VERSION ""

NS_ :

BS_:

BU_:

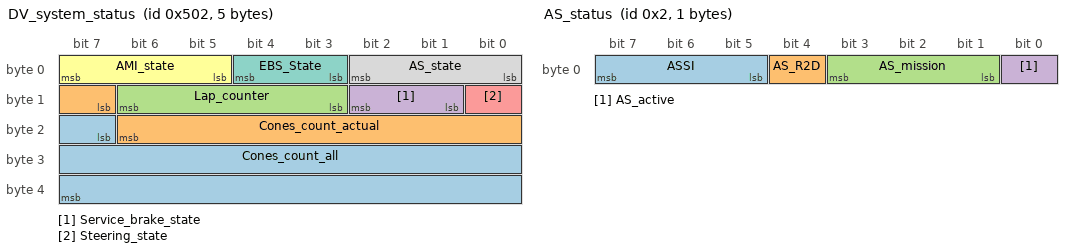
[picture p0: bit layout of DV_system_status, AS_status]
BO_ 1282 DV_system_status: 5 Vector__XXX
 SG_ Cones_count_all : 23|17@1+ (1,0) [0|16] "" Vector__XXX
 SG_ Cones_count_actual : 15|8@1+ (1,0) [0|7] "" Vector__XXX
 SG_ Lap_counter : 11|4@1+ (1,0) [0|3] "" Vector__XXX
 SG_ Service_brake_state : 9|2@1+ (1,0) [0|1] "" Vector__XXX
 SG_ Steering_state : 8|1@1+ (1,0) [0|0] "" Vector__XXX
 SG_ AMI_state : 5|3@1+ (1,0) [0|2] "" Vector__XXX
 SG_ EBS_State : 3|2@1+ (1,0) [0|1] "" Vector__XXX
 SG_ AS_state : 0|3@1+ (1,0) [0|2] "" Vector__XXX

BO_ 2 AS_status: 1 Vector__XXX
 SG_ ASSI : 5|3@1+ (1,0) [0|7] "enum" Vector__XXX
 SG_ AS_R2D : 4|1@1+ (1,0) [0|1] "bool" Vector__XXX
 SG_ AS_mission : 1|3@1+ (1,0) [0|7] "enum" Vector__XXX
 SG_ AS_active : 0|1@1+ (1,0) [0|1] "bool" Vector__XXX

BO_ 1 AS_Setpt_steer: 3 Vector__XXX
 SG_ AS_steer_ang : 0|24@1- (0.005,0) [-41943.04|41943.035] "rad" Vector__XXX

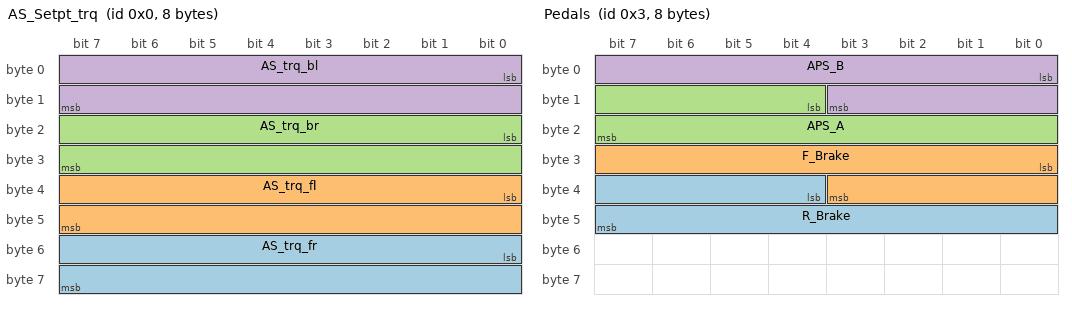
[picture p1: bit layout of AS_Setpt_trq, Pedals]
BO_ 0 AS_Setpt_trq: 8 Vector__XXX
 SG_ AS_trq_fr : 48|16@1- (0.0098,0) [-321.1264|321.1166] "Nm" Vector__XXX
 SG_ AS_trq_fl : 32|16@1- (0.0098,0) [-321.1264|321.1166] "Nm" Vector__XXX
 SG_ AS_trq_br : 16|16@1- (0.0098,0) [-321.1264|321.1166] "Nm" Vector__XXX
 SG_ AS_trq_bl : 0|16@1- (0.0098,0) [-321.1264|321.1166] "Nm" Vector__XXX

BO_ 3 Pedals: 8 Vector__XXX
 SG_ R_Brake : 36|12@1+ (0.6103,-249.978) [0|2249.2005] "psi" Vector__XXX
 SG_ F_Brake : 24|12@1+ (0.6103,-249.978) [0|2249.2005] "psi" Vector__XXX
 SG_ APS_A : 12|12@1+ (1,0) [0|4095] "percent" Vector__XXX
 SG_ APS_B : 0|12@1+ (1,0) [0|4095] "percent" Vector__XXX

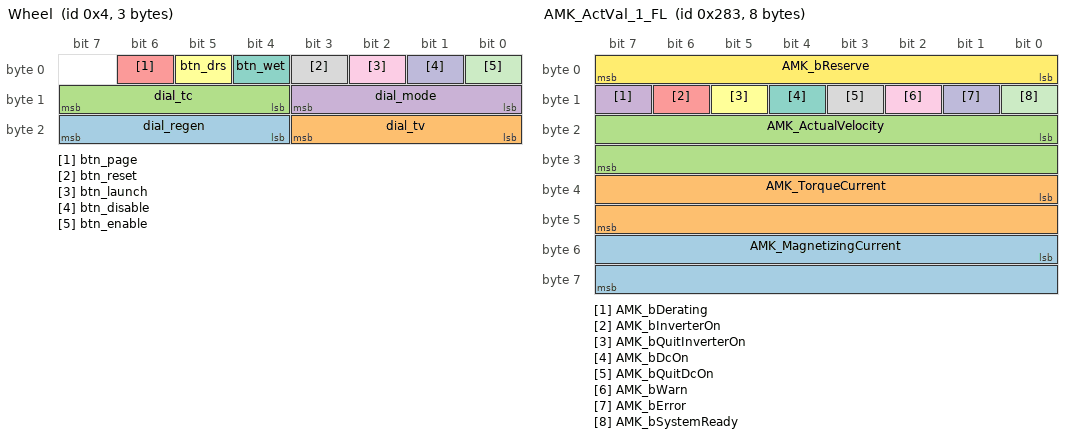
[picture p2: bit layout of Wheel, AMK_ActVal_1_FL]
BO_ 4 Wheel: 3 Vector__XXX
 SG_ dial_regen : 20|4@1+ (1,0) [0|15] "" Vector__XXX
 SG_ dial_tv : 16|4@1+ (1,0) [0|15] "" Vector__XXX
 SG_ dial_tc : 12|4@1+ (1,0) [0|15] "" Vector__XXX
 SG_ dial_mode : 8|4@1+ (1,0) [0|15] "" Vector__XXX
 SG_ btn_page : 6|1@1+ (1,0) [0|1] "" Vector__XXX
 SG_ btn_drs : 5|1@1+ (1,0) [0|1] "" Vector__XXX
 SG_ btn_wet : 4|1@1+ (1,0) [0|1] "" Vector__XXX
 SG_ btn_reset : 3|1@1+ (1,0) [0|1] "" Vector__XXX
 SG_ btn_launch : 2|1@1+ (1,0) [0|1] "" Vector__XXX
 SG_ btn_disable : 1|1@1+ (1,0) [0|1] "" Vector__XXX
 SG_ btn_enable : 0|1@1+ (1,0) [0|1] "" Vector__XXX

BO_ 643 AMK_ActVal_1_FL: 8 Vector__XXX
 SG_ AMK_MagnetizingCurrent : 48|16@1- (1,0) [-32768|32767] "" Vector__XXX
 SG_ AMK_TorqueCurrent : 32|16@1- (1,0) [-32768|32767] "" Vector__XXX
 SG_ AMK_ActualVelocity : 16|16@1- (1,0) [-32768|32767] "rpm" Vector__XXX
 SG_ AMK_bDerating : 15|1@1+ (1,0) [0|1] "" Vector__XXX
 SG_ AMK_bInverterOn : 14|1@1+ (1,0) [0|1] "" Vector__XXX
 SG_ AMK_bQuitInverterOn : 13|1@1+ (1,0) [0|1] "" Vector__XXX
 SG_ AMK_bDcOn : 12|1@1+ (1,0) [0|1] "" Vector__XXX
 SG_ AMK_bQuitDcOn : 11|1@1+ (1,0) [0|1] "" Vector__XXX
 SG_ AMK_bWarn : 10|1@1+ (1,0) [0|1] "" Vector__XXX
 SG_ AMK_bError : 9|1@1+ (1,0) [0|1] "" Vector__XXX
 SG_ AMK_bSystemReady : 8|1@1+ (1,0) [0|1] "" Vector__XXX
 SG_ AMK_bReserve : 0|8@1+ (1,0) [0|255] "" Vector__XXX

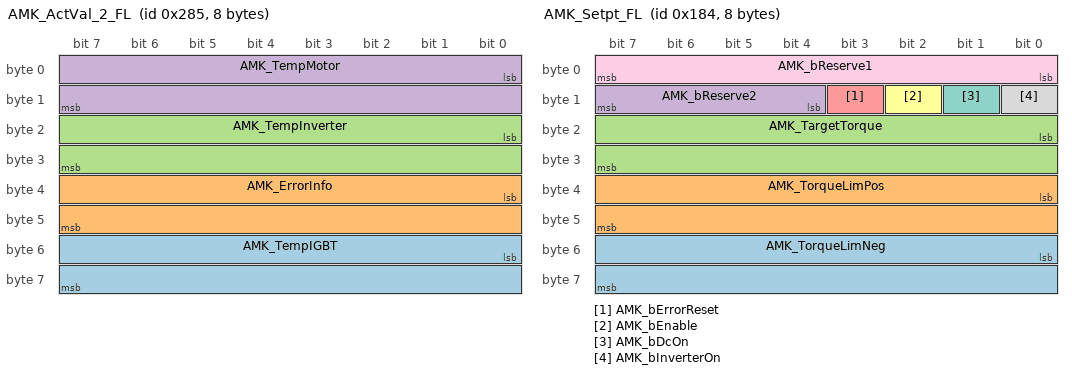
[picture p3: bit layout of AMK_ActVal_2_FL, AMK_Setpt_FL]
BO_ 645 AMK_ActVal_2_FL: 8 Vector__XXX
 SG_ AMK_TempIGBT : 48|16@1- (0.1,0) [-3276.8|3276.7] "C" Vector__XXX
 SG_ AMK_ErrorInfo : 32|16@1+ (1,0) [0|65535] "" Vector__XXX
 SG_ AMK_TempInverter : 16|16@1- (0.1,0) [-3276.8|3276.7] "C" Vector__XXX
 SG_ AMK_TempMotor : 0|16@1- (0.1,0) [-3276.8|3276.7] "C" Vector__XXX

BO_ 388 AMK_Setpt_FL: 8 Vector__XXX
 SG_ AMK_TorqueLimNeg : 48|16@1- (0.0098,0) [-321.1264|321.1166] "Nm" Vector__XXX
 SG_ AMK_TorqueLimPos : 32|16@1- (0.0098,0) [-321.1264|321.1166] "Nm" Vector__XXX
 SG_ AMK_TargetTorque : 16|16@1- (0.0098,0) [-321.1264|321.1166] "Nm" Vector__XXX
 SG_ AMK_bReserve2 : 12|4@1+ (1,0) [0|15] "" Vector__XXX
 SG_ AMK_bErrorReset : 11|1@1+ (1,0) [0|1] "" Vector__XXX
 SG_ AMK_bEnable : 10|1@1+ (1,0) [0|1] "" Vector__XXX
 SG_ AMK_bDcOn : 9|1@1+ (1,0) [0|1] "" Vector__XXX
 SG_ AMK_bInverterOn : 8|1@1+ (1,0) [0|1] "" Vector__XXX
 SG_ AMK_bReserve1 : 0|8@1+ (1,0) [0|255] "" Vector__XXX

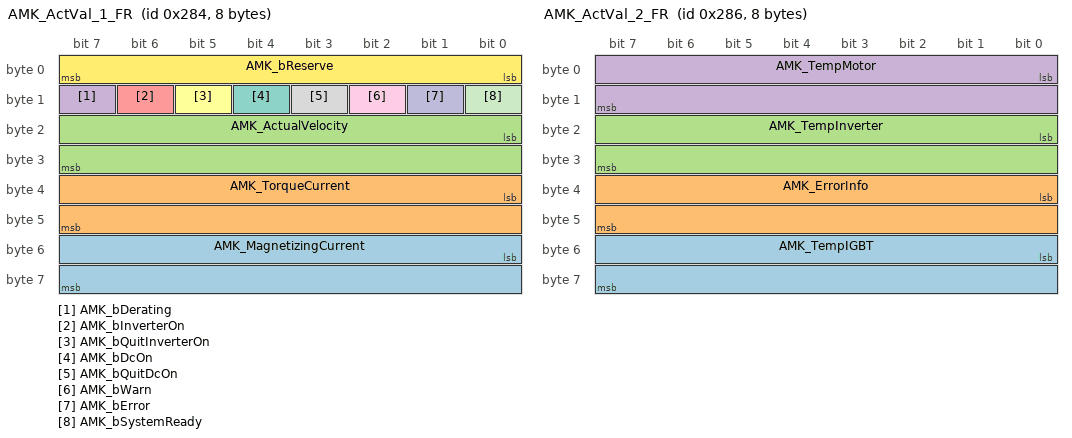
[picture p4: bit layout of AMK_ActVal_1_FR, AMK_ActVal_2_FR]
BO_ 644 AMK_ActVal_1_FR: 8 Vector__XXX
 SG_ AMK_MagnetizingCurrent : 48|16@1- (1,0) [-32768|32767] "" Vector__XXX
 SG_ AMK_TorqueCurrent : 32|16@1- (1,0) [-32768|32767] "" Vector__XXX
 SG_ AMK_ActualVelocity : 16|16@1- (1,0) [-32768|32767] "rpm" Vector__XXX
 SG_ AMK_bDerating : 15|1@1+ (1,0) [0|1] "" Vector__XXX
 SG_ AMK_bInverterOn : 14|1@1+ (1,0) [0|1] "" Vector__XXX
 SG_ AMK_bQuitInverterOn : 13|1@1+ (1,0) [0|1] "" Vector__XXX
 SG_ AMK_bDcOn : 12|1@1+ (1,0) [0|1] "" Vector__XXX
 SG_ AMK_bQuitDcOn : 11|1@1+ (1,0) [0|1] "" Vector__XXX
 SG_ AMK_bWarn : 10|1@1+ (1,0) [0|1] "" Vector__XXX
 SG_ AMK_bError : 9|1@1+ (1,0) [0|1] "" Vector__XXX
 SG_ AMK_bSystemReady : 8|1@1+ (1,0) [0|1] "" Vector__XXX
 SG_ AMK_bReserve : 0|8@1+ (1,0) [0|255] "" Vector__XXX

BO_ 646 AMK_ActVal_2_FR: 8 Vector__XXX
 SG_ AMK_TempIGBT : 48|16@1- (0.1,0) [-3276.8|3276.7] "C" Vector__XXX
 SG_ AMK_ErrorInfo : 32|16@1+ (1,0) [0|65535] "" Vector__XXX
 SG_ AMK_TempInverter : 16|16@1- (0.1,0) [-3276.8|3276.7] "C" Vector__XXX
 SG_ AMK_TempMotor : 0|16@1- (0.1,0) [-3276.8|3276.7] "C" Vector__XXX

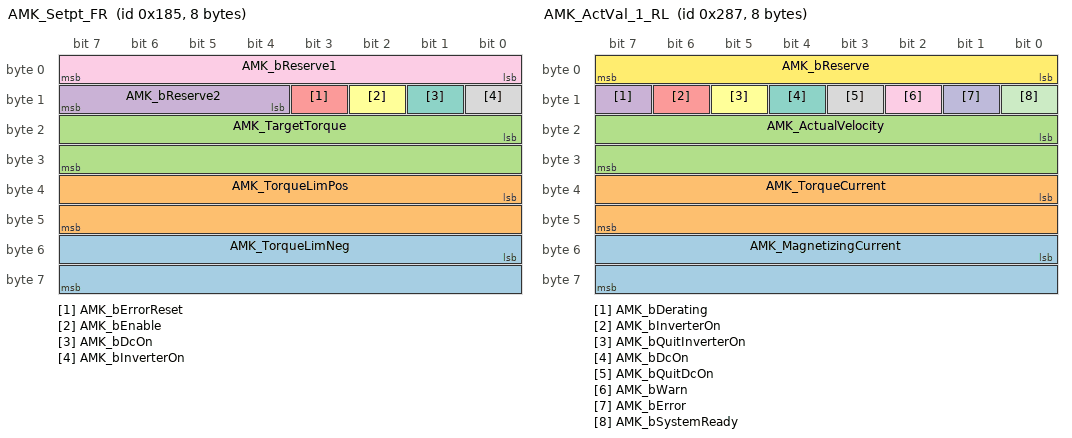
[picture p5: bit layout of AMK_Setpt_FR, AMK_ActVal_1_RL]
BO_ 389 AMK_Setpt_FR: 8 Vector__XXX
 SG_ AMK_TorqueLimNeg : 48|16@1- (0.0098,0) [-321.1264|321.1166] "Nm" Vector__XXX
 SG_ AMK_TorqueLimPos : 32|16@1- (0.0098,0) [-321.1264|321.1166] "Nm" Vector__XXX
 SG_ AMK_TargetTorque : 16|16@1- (0.0098,0) [-321.1264|321.1166] "Nm" Vector__XXX
 SG_ AMK_bReserve2 : 12|4@1+ (1,0) [0|15] "" Vector__XXX
 SG_ AMK_bErrorReset : 11|1@1+ (1,0) [0|1] "" Vector__XXX
 SG_ AMK_bEnable : 10|1@1+ (1,0) [0|1] "" Vector__XXX
 SG_ AMK_bDcOn : 9|1@1+ (1,0) [0|1] "" Vector__XXX
 SG_ AMK_bInverterOn : 8|1@1+ (1,0) [0|1] "" Vector__XXX
 SG_ AMK_bReserve1 : 0|8@1+ (1,0) [0|255] "" Vector__XXX

BO_ 647 AMK_ActVal_1_RL: 8 Vector__XXX
 SG_ AMK_MagnetizingCurrent : 48|16@1- (1,0) [-32768|32767] "" Vector__XXX
 SG_ AMK_TorqueCurrent : 32|16@1- (1,0) [-32768|32767] "" Vector__XXX
 SG_ AMK_ActualVelocity : 16|16@1- (1,0) [-32768|32767] "rpm" Vector__XXX
 SG_ AMK_bDerating : 15|1@1+ (1,0) [0|1] "" Vector__XXX
 SG_ AMK_bInverterOn : 14|1@1+ (1,0) [0|1] "" Vector__XXX
 SG_ AMK_bQuitInverterOn : 13|1@1+ (1,0) [0|1] "" Vector__XXX
 SG_ AMK_bDcOn : 12|1@1+ (1,0) [0|1] "" Vector__XXX
 SG_ AMK_bQuitDcOn : 11|1@1+ (1,0) [0|1] "" Vector__XXX
 SG_ AMK_bWarn : 10|1@1+ (1,0) [0|1] "" Vector__XXX
 SG_ AMK_bError : 9|1@1+ (1,0) [0|1] "" Vector__XXX
 SG_ AMK_bSystemReady : 8|1@1+ (1,0) [0|1] "" Vector__XXX
 SG_ AMK_bReserve : 0|8@1+ (1,0) [0|255] "" Vector__XXX

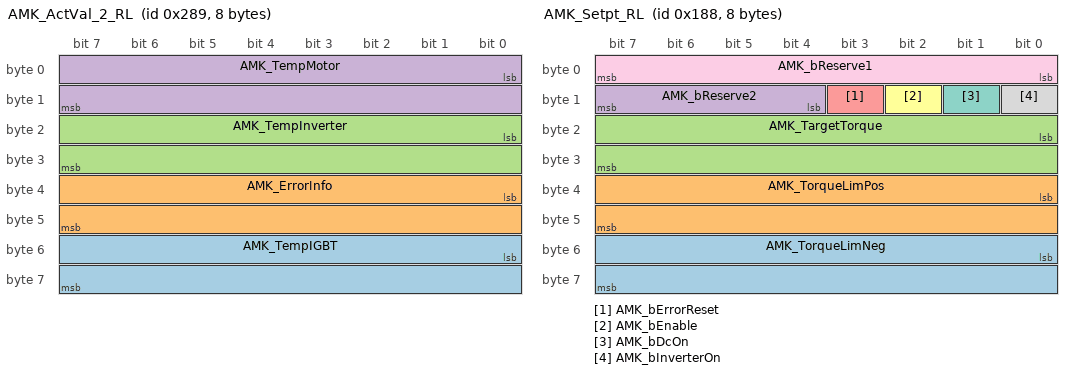
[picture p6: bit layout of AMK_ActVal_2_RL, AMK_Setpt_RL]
BO_ 649 AMK_ActVal_2_RL: 8 Vector__XXX
 SG_ AMK_TempIGBT : 48|16@1- (0.1,0) [-3276.8|3276.7] "C" Vector__XXX
 SG_ AMK_ErrorInfo : 32|16@1+ (1,0) [0|65535] "" Vector__XXX
 SG_ AMK_TempInverter : 16|16@1- (0.1,0) [-3276.8|3276.7] "C" Vector__XXX
 SG_ AMK_TempMotor : 0|16@1- (0.1,0) [-3276.8|3276.7] "C" Vector__XXX

BO_ 392 AMK_Setpt_RL: 8 Vector__XXX
 SG_ AMK_TorqueLimNeg : 48|16@1- (0.0098,0) [-321.1264|321.1166] "Nm" Vector__XXX
 SG_ AMK_TorqueLimPos : 32|16@1- (0.0098,0) [-321.1264|321.1166] "Nm" Vector__XXX
 SG_ AMK_TargetTorque : 16|16@1- (0.0098,0) [-321.1264|321.1166] "Nm" Vector__XXX
 SG_ AMK_bReserve2 : 12|4@1+ (1,0) [0|15] "" Vector__XXX
 SG_ AMK_bErrorReset : 11|1@1+ (1,0) [0|1] "" Vector__XXX
 SG_ AMK_bEnable : 10|1@1+ (1,0) [0|1] "" Vector__XXX
 SG_ AMK_bDcOn : 9|1@1+ (1,0) [0|1] "" Vector__XXX
 SG_ AMK_bInverterOn : 8|1@1+ (1,0) [0|1] "" Vector__XXX
 SG_ AMK_bReserve1 : 0|8@1+ (1,0) [0|255] "" Vector__XXX

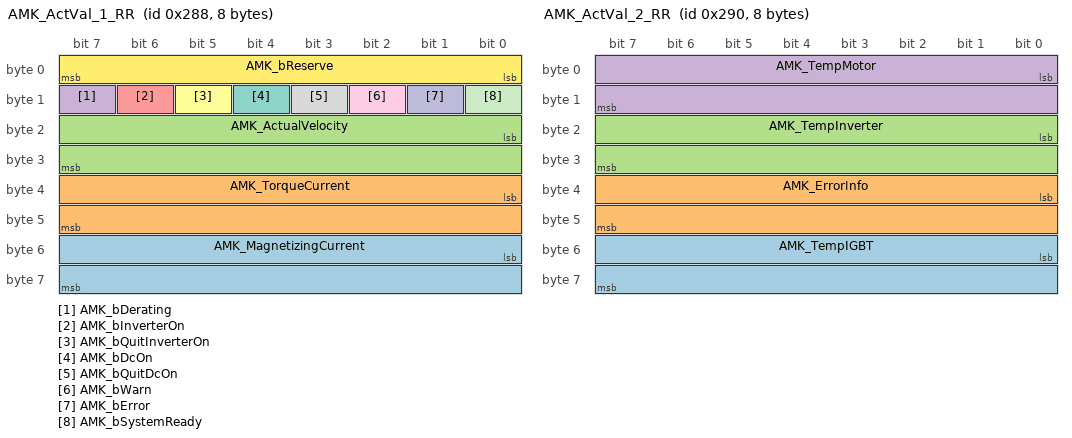
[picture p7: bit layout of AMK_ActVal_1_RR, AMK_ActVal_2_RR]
BO_ 648 AMK_ActVal_1_RR: 8 Vector__XXX
 SG_ AMK_MagnetizingCurrent : 48|16@1- (1,0) [-32768|32767] "" Vector__XXX
 SG_ AMK_TorqueCurrent : 32|16@1- (1,0) [-32768|32767] "" Vector__XXX
 SG_ AMK_ActualVelocity : 16|16@1- (1,0) [-32768|32767] "rpm" Vector__XXX
 SG_ AMK_bDerating : 15|1@1+ (1,0) [0|1] "" Vector__XXX
 SG_ AMK_bInverterOn : 14|1@1+ (1,0) [0|1] "" Vector__XXX
 SG_ AMK_bQuitInverterOn : 13|1@1+ (1,0) [0|1] "" Vector__XXX
 SG_ AMK_bDcOn : 12|1@1+ (1,0) [0|1] "" Vector__XXX
 SG_ AMK_bQuitDcOn : 11|1@1+ (1,0) [0|1] "" Vector__XXX
 SG_ AMK_bWarn : 10|1@1+ (1,0) [0|1] "" Vector__XXX
 SG_ AMK_bError : 9|1@1+ (1,0) [0|1] "" Vector__XXX
 SG_ AMK_bSystemReady : 8|1@1+ (1,0) [0|1] "" Vector__XXX
 SG_ AMK_bReserve : 0|8@1+ (1,0) [0|255] "" Vector__XXX

BO_ 656 AMK_ActVal_2_RR: 8 Vector__XXX
 SG_ AMK_TempIGBT : 48|16@1- (0.1,0) [-3276.8|3276.7] "C" Vector__XXX
 SG_ AMK_ErrorInfo : 32|16@1+ (1,0) [0|65535] "" Vector__XXX
 SG_ AMK_TempInverter : 16|16@1- (0.1,0) [-3276.8|3276.7] "C" Vector__XXX
 SG_ AMK_TempMotor : 0|16@1- (0.1,0) [-3276.8|3276.7] "C" Vector__XXX

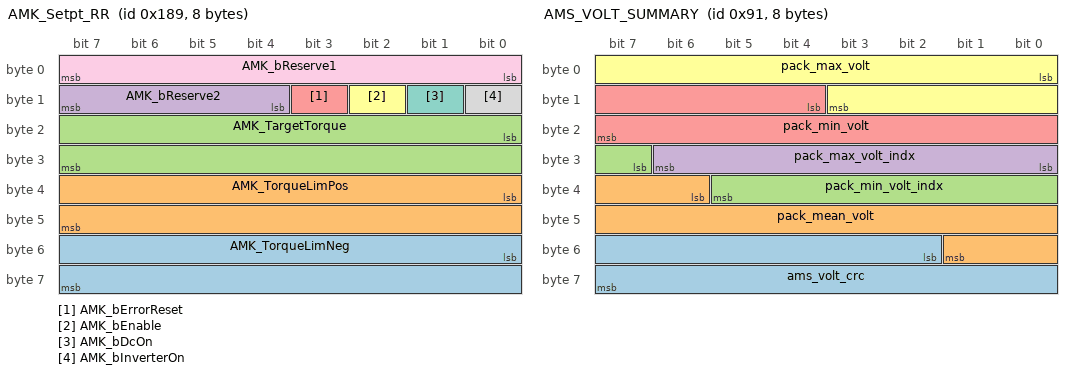
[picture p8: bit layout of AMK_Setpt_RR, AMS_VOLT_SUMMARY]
BO_ 393 AMK_Setpt_RR: 8 Vector__XXX
 SG_ AMK_TorqueLimNeg : 48|16@1- (0.0098,0) [-321.1264|321.1166] "Nm" Vector__XXX
 SG_ AMK_TorqueLimPos : 32|16@1- (0.0098,0) [-321.1264|321.1166] "Nm" Vector__XXX
 SG_ AMK_TargetTorque : 16|16@1- (0.0098,0) [-321.1264|321.1166] "Nm" Vector__XXX
 SG_ AMK_bReserve2 : 12|4@1+ (1,0) [0|15] "" Vector__XXX
 SG_ AMK_bErrorReset : 11|1@1+ (1,0) [0|1] "" Vector__XXX
 SG_ AMK_bEnable : 10|1@1+ (1,0) [0|1] "" Vector__XXX
 SG_ AMK_bDcOn : 9|1@1+ (1,0) [0|1] "" Vector__XXX
 SG_ AMK_bInverterOn : 8|1@1+ (1,0) [0|1] "" Vector__XXX
 SG_ AMK_bReserve1 : 0|8@1+ (1,0) [0|255] "" Vector__XXX

BO_ 144 AMS_STATUS: 8 Vector__XXX
 SG_ dcdc_on : 63|1@1+ (1,0) [0|1] "" Vector__XXX
 SG_ bus_voltage : 50|13@1+ (0.075,0) [0|614.325] "V" Vector__XXX
 SG_ pack_SDC_stat : 49|1@1+ (1,0) [0|1] "" Vector__XXX
 SG_ pack_RR_stat : 48|1@1+ (1,0) [0|1] "" Vector__XXX
 SG_ pack_RL_stat : 47|1@1+ (1,0) [0|1] "" Vector__XXX
 SG_ pack_FR_stat : 46|1@1+ (1,0) [0|1] "" Vector__XXX
 SG_ pack_FL_stat : 45|1@1+ (1,0) [0|1] "" Vector__XXX
 SG_ pack_MC_stat : 44|1@1+ (1,0) [0|1] "" Vector__XXX
 SG_ pack_TSAC_stat : 43|1@1+ (1,0) [0|1] "" Vector__XXX
 SG_ pack_HVD_stat : 42|1@1+ (1,0) [0|1] "" Vector__XXX
 SG_ pack_charge_stat : 41|1@1+ (1,0) [0|1] "" Vector__XXX
 SG_ pack_balance_stat : 40|1@1+ (1,0) [0|1] "" Vector__XXX
 SG_ pack_BSPD_stat : 39|1@1+ (1,0) [0|1] "" Vector__XXX
 SG_ pack_IMD_stat : 38|1@1+ (1,0) [0|1] "" Vector__XXX
 SG_ ams_CAN_nonlatch_fault : 37|1@1+ (1,0) [0|1] "" Vector__XXX
 SG_ ams_CAN_latch_fault : 36|1@1+ (1,0) [0|1] "" Vector__XXX
 SG_ ams_eeprom_fail : 35|1@1+ (1,0) [0|1] "" Vector__XXX
 SG_ pack_link_fault : 34|1@1+ (1,0) [0|1] "" Vector__XXX
 SG_ pack_OC : 33|1@1+ (1,0) [0|1] "" Vector__XXX
 SG_ pack_s4_timeout : 32|1@1+ (1,0) [0|1] "" Vector__XXX
 SG_ pack_s3_timeout : 31|1@1+ (1,0) [0|1] "" Vector__XXX
 SG_ pack_s2_timeout : 30|1@1+ (1,0) [0|1] "" Vector__XXX
 SG_ pack_s1_timeout : 29|1@1+ (1,0) [0|1] "" Vector__XXX
 SG_ pack_OT : 28|1@1+ (1,0) [0|1] "" Vector__XXX
 SG_ pack_UV : 27|1@1+ (1,0) [0|1] "" Vector__XXX
 SG_ pack_OV : 26|1@1+ (1,0) [0|1] "" Vector__XXX
 SG_ pack_ready2drive : 25|1@1+ (1,0) [0|1] "" Vector__XXX
 SG_ pack_soc : 13|12@1+ (0.025,0) [0|102.375] "%" Vector__XXX
 SG_ pack_voltage : 0|13@1+ (0.075,0) [0|614.325] "V" Vector__XXX

BO_ 145 AMS_VOLT_SUMMARY: 8 Vector__XXX
 SG_ ams_volt_crc : 50|14@1+ (1,0) [0|16383] "" Vector__XXX
 SG_ pack_mean_volt : 38|12@1+ (0.0015,0) [0|6.1425] "V" Vector__XXX
 SG_ pack_min_volt_indx : 31|7@1+ (1,0) [0|127] "" Vector__XXX
 SG_ pack_max_volt_indx : 24|7@1+ (1,0) [0|127] "" Vector__XXX
 SG_ pack_min_volt : 12|12@1+ (0.0015,0) [0|6.1425] "V" Vector__XXX
 SG_ pack_max_volt : 0|12@1+ (0.0015,0) [0|6.1425] "V" Vector__XXX

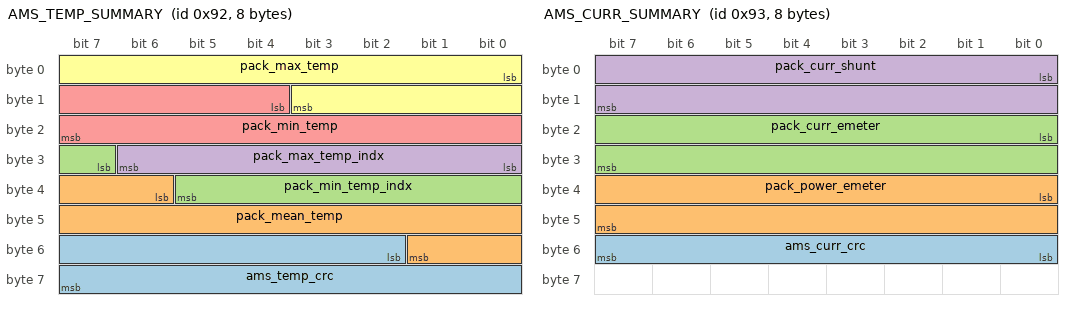
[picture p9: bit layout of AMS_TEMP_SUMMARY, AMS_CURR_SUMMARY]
BO_ 146 AMS_TEMP_SUMMARY: 8 Vector__XXX
 SG_ ams_temp_crc : 50|14@1+ (1,0) [0|16383] "" Vector__XXX
 SG_ pack_mean_temp : 38|12@1- (0.1,0) [-204.8|204.7] "degC" Vector__XXX
 SG_ pack_min_temp_indx : 31|7@1+ (1,0) [0|127] "" Vector__XXX
 SG_ pack_max_temp_indx : 24|7@1+ (1,0) [0|127] "" Vector__XXX
 SG_ pack_min_temp : 12|12@1- (0.1,0) [-204.8|204.7] "degC" Vector__XXX
 SG_ pack_max_temp : 0|12@1- (0.1,0) [-204.8|204.7] "degC" Vector__XXX

BO_ 147 AMS_CURR_SUMMARY: 8 Vector__XXX
 SG_ ams_curr_crc : 48|8@1+ (1,0) [0|255] "" Vector__XXX
 SG_ pack_power_emeter : 32|16@1- (3,0) [-98304|98301] "W" Vector__XXX
 SG_ pack_curr_emeter : 16|16@1- (0.015,0) [-491.52|491.505] "A" Vector__XXX
 SG_ pack_curr_shunt : 0|16@1- (0.015,0) [-491.52|491.505] "A" Vector__XXX

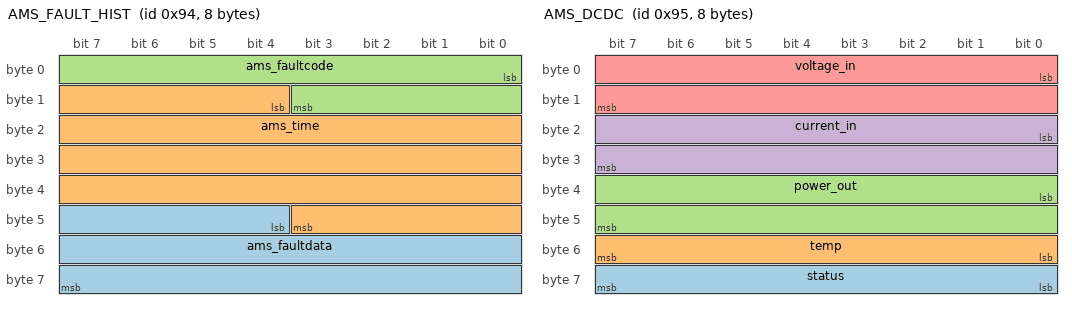
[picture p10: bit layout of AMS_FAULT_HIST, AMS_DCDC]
BO_ 148 AMS_FAULT_HIST: 8 Vector__XXX
 SG_ ams_faultdata : 44|20@1+ (1,0) [0|1048575] "" Vector__XXX
 SG_ ams_time : 12|32@1+ (1,0) [0|4294967295] "" Vector__XXX
 SG_ ams_faultcode : 0|12@1+ (1,0) [0|4095] "" Vector__XXX

BO_ 149 AMS_DCDC: 8 Vector__XXX
 SG_ status : 56|8@1+ (1,0) [0|255] "" Vector__XXX
 SG_ temp : 48|8@1+ (1,0) [0|255] "C" Vector__XXX
 SG_ power_out : 32|16@1+ (1,0) [0|65535] "W" Vector__XXX
 SG_ current_in : 16|16@1+ (0.001,0) [0|65.535] "A" Vector__XXX
 SG_ voltage_in : 0|16@1+ (0.1,0) [0|6553.5] "V" Vector__XXX

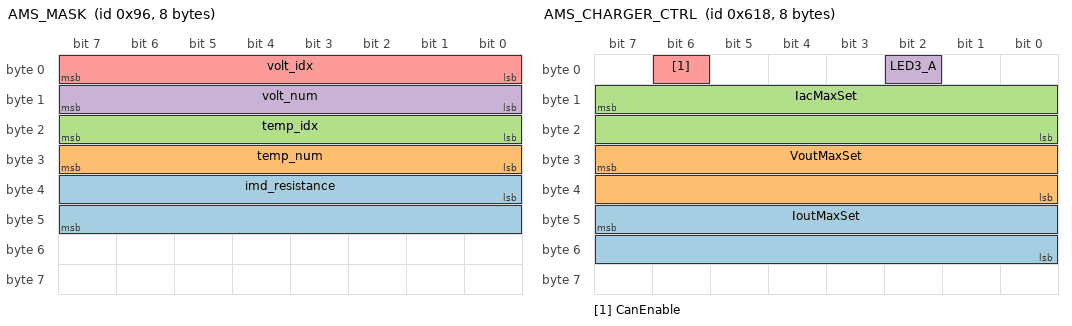
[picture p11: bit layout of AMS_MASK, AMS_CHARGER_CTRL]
BO_ 150 AMS_MASK: 8 Vector__XXX
 SG_ imd_resistance : 32|16@1+ (1,0) [0|65535] "" Vector__XXX
 SG_ temp_num : 24|8@1+ (1,0) [0|255] "" Vector__XXX
 SG_ temp_idx : 16|8@1+ (1,0) [0|255] "" Vector__XXX
 SG_ volt_num : 8|8@1+ (1,0) [0|255] "" Vector__XXX
 SG_ volt_idx : 0|8@1+ (1,0) [0|255] "" Vector__XXX

BO_ 1560 AMS_CHARGER_CTRL: 8 Vector__XXX
 SG_ IoutMaxSet : 47|16@0+ (0.1,0) [0|6553.5] "A" Vector__XXX
 SG_ VoutMaxSet : 31|16@0+ (0.1,0) [0|6553.5] "V" Vector__XXX
 SG_ IacMaxSet : 15|16@0+ (0.1,0) [0|6553.5] "A" Vector__XXX
 SG_ LED3_A : 2|1@0+ (1,0) [0|1] "" Vector__XXX
 SG_ CanEnable : 6|1@0+ (1,0) [0|1] "" Vector__XXX

BO_ 1557 AMS_CHARGER_TST: 8 Vector__XXX
 SG_ cntHours : 55|16@0- (1,0) [-32768|32767] "hours" Vector__XXX
 SG_ S2Ok : 34|1@0+ (1,0) [0|1] "" Vector__XXX
 SG_ PilotOk : 36|1@0+ (1,0) [0|1] "" Vector__XXX
 SG_ ProxOk : 38|1@0+ (1,0) [0|1] "" Vector__XXX
 SG_ Ignition : 24|1@0+ (1,0) [0|1] "" Vector__XXX
 SG_ IacFail : 25|1@0+ (1,0) [0|1] "" Vector__XXX
 SG_ ThreePhase : 28|1@0+ (1,0) [0|1] "" Vector__XXX
 SG_ Neutro2 : 29|1@0+ (1,0) [0|1] "" Vector__XXX
 SG_ Neutro1 : 30|1@0+ (1,0) [0|1] "" Vector__XXX
 SG_ CoolingFail : 16|1@0+ (1,0) [0|1] "" Vector__XXX
 SG_ HVrxFail : 17|1@0+ (1,0) [0|1] "" Vector__XXX
 SG_ FANon : 18|1@0+ (1,0) [0|1] "" Vector__XXX
 SG_ PUMPon : 19|1@0+ (1,0) [0|1] "" Vector__XXX
 SG_ bulk3_fail : 20|1@0+ (1,0) [0|1] "" Vector__XXX
 SG_ bulk2_fail : 21|1@0+ (1,0) [0|1] "" Vector__XXX
 SG_ bulk1_fail : 22|1@0+ (1,0) [0|1] "" Vector__XXX
 SG_ LVBatteryNP : 23|1@0+ (1,0) [0|1] "" Vector__XXX
 SG_ TherFail : 9|1@0+ (1,0) [0|1] "" Vector__XXX
 SG_ connOpen : 13|1@0+ (1,0) [0|1] "" Vector__XXX
 SG_ ovp : 14|1@0+ (1,0) [0|1] "" Vector__XXX
 SG_ Rx619fail : 15|1@0+ (1,0) [0|1] "" Vector__XXX
 SG_ LED618 : 0|1@0+ (1,0) [0|1] "" Vector__XXX
 SG_ LED3 : 1|1@0+ (1,0) [0|1] "" Vector__XXX
 SG_ Neutral : 2|1@0+ (1,0) [0|1] "" Vector__XXX
 SG_ VoutOk : 3|1@0+ (1,0) [0|1] "" Vector__XXX
 SG_ PwrOk : 4|1@0+ (1,0) [0|1] "" Vector__XXX
 SG_ PrCompl : 5|1@0+ (1,0) [0|1] "" Vector__XXX
 SG_ Acok : 6|1@0+ (1,0) [0|1] "" Vector__XXX
 SG_ rx618Fail : 7|1@0+ (1,0) [0|1] "" Vector__XXX

BO_ 1561 AMS_BALANCE_CTRL: 8 Vector__XXX
 SG_ balance_en : 11|1@1+ (1,0) [0|1] "" Vector__XXX
 SG_ balance_safety_cut_volt : 0|11@1+ (0.002,0) [0|4.094] "V" Vector__XXX

CM_ BO_ 1282 "Official name in datasheet is DV system status, but CAN message names have to have underscores ";
